# ATSAMRH707F18A register map
Vendor: Microchip Technology; Series: SAMRH707; File version: 0
CPU: CM7 r1p1, little endian, MPU, FPU, double-precision FPU, I-cache, D-cache, ITCM, DTCM, 3 interrupt priority bits, 69 interrupts
Registers are 32-bit, read-write, reset 0x0 unless marked. A register's access mark holds for its fields unless they carry their own. Offsets are from the block's base; [hi:lo] are bit positions; {n}, {i} and the like mark numbered series; 'fields as' and 'values as' point back to an identical list.

## SFR — Special Function Registers
Base 0x400A0000
{0x0+4i} ROMCODE_DBG[{i}] (i=0..39) — ROM code debug
  [31:0] ROM_CODE_DEBUG — Rom code debug step
0xA0 CAN0 — CAN0 MSB Base Address
  [31:16] EXT_MEM_ADDR — MSB Base Address
0xA4 CAN1 — CAN1 MSB Base Address
  [31:16] EXT_MEM_ADDR — MSB Base Address
0xB0 BOOT_CFG — BOOT Configuration
  [2:0] BOOT_SEL — BOOT_MODE selected
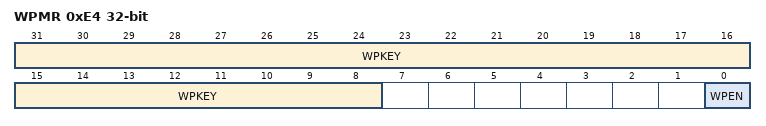
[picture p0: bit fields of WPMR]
0xE4 WPMR — Write Protection Mode Register
  [31:8] WPKEY — Write Protection Key
    0x534652=PASSWD (Writing any other value in this field aborts the write operation of the WPEN bit. Always reads as 0.)
  [0] WPEN — Write Protection Enable

## SUPC — Supply Controller
Base 0x40100210
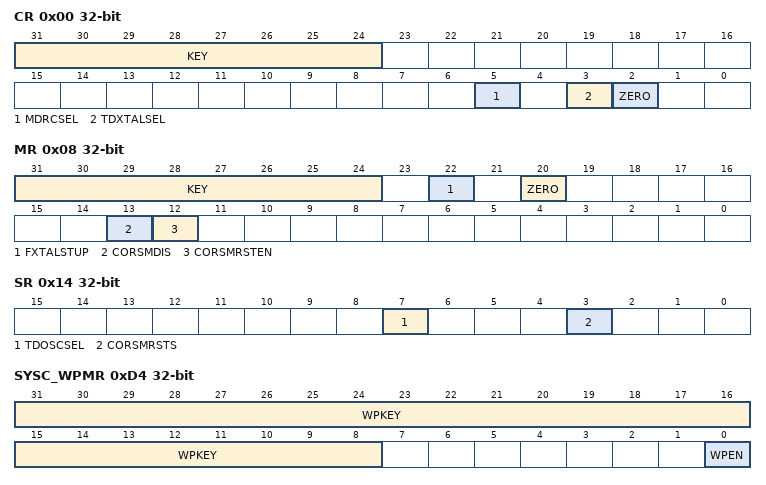
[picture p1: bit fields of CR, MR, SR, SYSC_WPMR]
0x00 CR wo — Supply Controller Control Register
  [31:24] KEY — Password
    165=PASSWD (Writing any other value in this field aborts the write operation.)
  [5] MDRCSEL — Monitoring Domain RC Oscillator Select
    0=NO_EFFECT; 1=CRYSTAL_SEL (If KEY is correct, XTALSEL switches the slow clock of the monitoring domain (MD_SLCK) on the slow RC oscillator output.)
  [3] TDXTALSEL — Timing Domain Crystal Oscillator Select
    0=NO_EFFECT; 1=CRYSTAL_SEL (If KEY is correct, XTALSEL switches the slow clock of the timing domain (TD_SLCK) on the 32.768 kHz crystal oscillator output.)
  [2] ZERO — Shall be always write at '0'
0x04 SMMR — Supply Controller Supply Monitor Mode Register
  [23] CORESMUSEL — Core Supply Monitor User Selection
0x08 MR — Supply Controller Mode Register
  [31:24] KEY — Password Key
    values as CR.KEY
  [22] FXTALSTUP — Fast Startup 32.768 kHz Crystal Oscillator
  [20] ZERO — Shall be always write at '0'
  [13] CORSMDIS — VDDCORE Supply Monitor Disable
    0=ENABLE (The VDDCORE supply monitor is enabled.); 1=DISABLE (The VDDCORE supply monitor is disabled.)
  [12] CORSMRSTEN — VDDCORE Supply Monitor Reset Enable
    0=NOT_ENABLE (The core reset signal vddcore_nreset is not affected when a VDDCORE supply monitor detection occurs.); 1=ENABLE (The core reset signal, vddcore_nreset is asserted when a VDDCORE supply monitor detection occurs.)
0x14 SR ro — Supply Controller Status Register
  [7] TDOSCSEL — 32 kHz Oscillator Selection Status
    0=RC (The timing domain slow clock, TD_SLCK, is generated by the slow RC oscillator.); 1=CRYST (The timing domain slow clock, TD_SLCK, is generated by the 32.768 kHz crystal oscillator.)
  [3] CORSMRSTS — VDDCORE Supply Monitor Reset Status (cleared on read)
    0=NO (No VDDCORE Supply Monitor reset event has been detected since the last read of the SUPC_SR.); 1=PRESENT (At least one VDDCORE Supply Monitor reset event has been detected since the last read of the SUPC_SR.)
0x1C PWR — Supply Controller Power Register
  [18] ZERO — MD_SLCK always generated by the slow RC oscillator
0xD4 SYSC_WPMR — Write Protection Mode Register
  [31:8] WPKEY — Write Protection Key.
    0x525443=PASSWD (Writing any other value in this field aborts the write operation of the WPEN bit. Always reads as 0.)
  [0] WPEN — Write Protection Enable

## TCMECC
Base 0x40100400
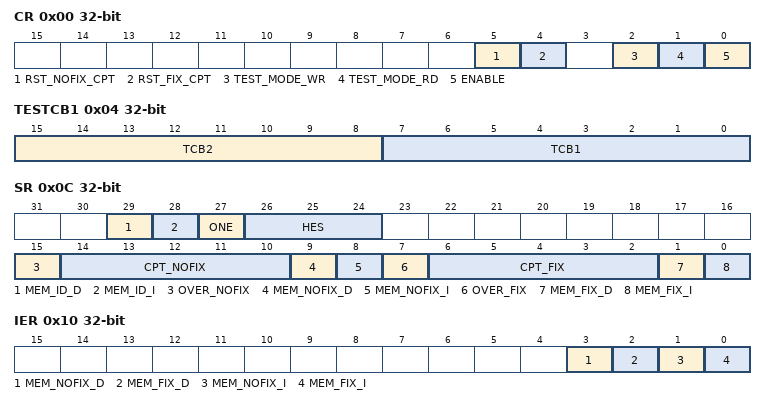
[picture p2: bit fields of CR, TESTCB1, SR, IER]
0x00 CR — TCMECC Control Register
  [5] RST_NOFIX_CPT — reset the un-fixable error counter
  [4] RST_FIX_CPT — reset the fixable error counter
  [2] TEST_MODE_WR — test mode of ECC protection - write mode
  [1] TEST_MODE_RD — test mode of ECC protection - read mode
  [0] ENABLE — ECC protection enable
0x04 TESTCB1 — TCMECC Test mode register 1
  [15:8] TCB2 — test check bit (8 bit)
  [7:0] TCB1 — test check bit (8 bit)
0x0C SR ro — TCMECC Status register
  [29] MEM_ID_D — memory identification number
  [28] MEM_ID_I — memory identification number
  [27] ONE
  [26:24] HES — Hardware Error Size
  [15] OVER_NOFIX — counter overflow
  [14:10] CPT_NOFIX — 5 bits counter
  [9] MEM_NOFIX_D — Un-fixable error status in data memory
  [8] MEM_NOFIX_I — Un-fixable error status in instruction memory
  [7] OVER_FIX — counter overflow
  [6:2] CPT_FIX — 5 bits counter
  [1] MEM_FIX_D — Fixable error status in data memory
  [0] MEM_FIX_I — Fixable error status in instruction memory
0x10 IER wo — TCMECC Interrupt Enable Register
  [3] MEM_NOFIX_D — Un-fixable error on data
  [2] MEM_FIX_D — Fixable error on data
  [1] MEM_NOFIX_I — Un-fixable error on instruction
  [0] MEM_FIX_I — Fixable error on instruction
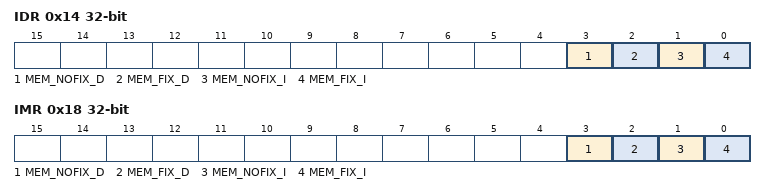
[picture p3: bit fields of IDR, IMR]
0x14 IDR wo — TCMECC Interrupt Disable Register
  [3] MEM_NOFIX_D — un-fixable error on data
  [2] MEM_FIX_D — fixable error on data
  [1] MEM_NOFIX_I — un-fixable error on instruction
  [0] MEM_FIX_I — fixable error on instruction
0x18 IMR ro — TCMECC Interrupt Mask Register
  fields as IDR
0x1C FAILAR ro — TCMECC Fail address register
  [31:0] ADDRESS — address of the error detected (refers to instruction memory)
0x20 FAILARD ro — TCMECC Fail address register data
  [31:0] ADDRESS — address of the error detected
0x24 FAILDR ro — TCMECC Fail data register
  [31:0] DATA — data of the error detected (refers to instruction memory)
0x28 FAILDRD ro — TCMECC Fail data register data
  fields as FAILDR
